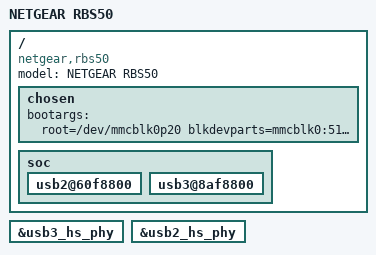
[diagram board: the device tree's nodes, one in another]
// SPDX-License-Identifier: GPL-2.0-or-later OR MIT

#include "qcom-ipq4019-orbi.dtsi"

/ {
	model = "NETGEAR RBS50";
	compatible = "netgear,rbs50";

	chosen {
		bootargs = "root=/dev/mmcblk0p20 blkdevparts=mmcblk0:512K@17K(0:SBL1)ro,512K(0:BOOTCONFIG)ro,512K(0:QSEE)ro,512K(0:QSEE_ALT)ro,256K(0:CDT)ro,256K(0:CDT_ALT)ro,256K(0:DDRPARAMS)ro,256K(0:APPSBLENV)ro,1M(0:APPSBL)ro,1M(0:APPSBL_ALT)ro,256K(0:ART)ro,256K(ARTMTD)ro,2M(language)ro,256K(config)ro,256K(pot)ro,256K(traffic_meter)ro,256K(pot_bak)ro,256K(traffic_meter.bak)ro,3840K(kernel),31488K(rootfs),35328K@9233K(firmware),256K(mtdoops)ro,1457651200(reserved)ro,-(unallocated) rootfstype=squashfs,ext4 rootwait";
	};

	soc {
		usb2@60f8800 {
			status = "okay";
		};

		usb3@8af8800 {
			status = "okay";
		};
	};
};

&usb3_hs_phy {
	status = "okay";
};

&usb2_hs_phy {
	status = "okay";
};
